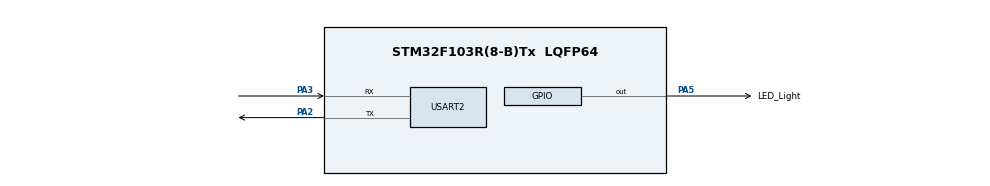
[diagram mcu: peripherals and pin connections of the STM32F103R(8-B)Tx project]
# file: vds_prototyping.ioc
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Dma.Request0=USART2_TX
Dma.USART2_TX.0.Direction=DMA_MEMORY_TO_PERIPH
Dma.USART2_TX.0.Instance=DMA1_Channel7
Dma.USART2_TX.0.MemDataAlignment=DMA_MDATAALIGN_BYTE
Dma.USART2_TX.0.MemInc=DMA_MINC_ENABLE
Dma.USART2_TX.0.Mode=DMA_NORMAL
Dma.USART2_TX.0.PeriphDataAlignment=DMA_PDATAALIGN_BYTE
Dma.USART2_TX.0.PeriphInc=DMA_PINC_DISABLE
Dma.USART2_TX.0.Priority=DMA_PRIORITY_LOW
FREERTOS.Tasks01=task1,24,128,startTask1,Default,NULL,Dynamic,NULL,NULL;myTask02,25,128,StartTask02,Default,NULL,Dynamic,NULL,NULL
Mcu.Family=STM32F1
Mcu.Name=STM32F103R(8-B)Tx
Mcu.Package=LQFP64
NVIC.DMA1_Channel7_IRQn=true\:5\:0\:false\:false\:true\:true\:false\:true\:true
NVIC.PriorityGroup=NVIC_PRIORITYGROUP_4
NVIC.TIM4_IRQn=true\:15\:0\:false\:false\:true\:false\:false\:true\:true
NVIC.TimeBase=TIM4_IRQn
NVIC.TimeBaseIP=TIM4
PA2.Mode=Asynchronous
PA2.Signal=USART2_TX
PA3.Mode=Asynchronous
PA3.Signal=USART2_RX
PA5.GPIO_Label=LED_Light
PA5.Signal=GPIO_Output
ProjectManager.HeapSize=0x200
ProjectManager.StackSize=0x400
ProjectManager.TargetToolchain=STM32CubeIDE
RCC.APB1Freq_Value=8000000
RCC.APB2Freq_Value=8000000
USART2.VirtualMode=VM_ASYNC
VP_FREERTOS_VS_CMSIS_V2.Mode=CMSIS_V2
VP_SYS_VS_tim4.Mode=TIM4
board=custom

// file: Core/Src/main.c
/* USER CODE BEGIN Header */
/**
  ******************************************************************************
  * @file           : main.c
  * @brief          : Main program body
  ******************************************************************************
  * @attention
  *
  * Copyright (c) 2024 STMicroelectronics.
  * All rights reserved.
  *
  * This software is licensed under terms that can be found in the LICENSE file
  * in the root directory of this software component.
  * If no LICENSE file comes with this software, it is provided AS-IS.
  *
  ******************************************************************************
  */
/* USER CODE END Header */
#include "main.h"
#include "cmsis_os.h"

/* USER CODE BEGIN Includes */
#include "stdio.h"
#include "string.h"

/* USER CODE END Includes */

UART_HandleTypeDef huart2;
DMA_HandleTypeDef hdma_usart2_tx;

/* Definitions for task1 */
osThreadId_t task1Handle;
const osThreadAttr_t task1_attributes = {
  .name = "task1",
  .stack_size = 128 * 4,
  .priority = (osPriority_t) osPriorityNormal,
};
/* Definitions for myTask02 */
osThreadId_t myTask02Handle;
const osThreadAttr_t myTask02_attributes = {
  .name = "myTask02",
  .stack_size = 128 * 4,
  .priority = (osPriority_t) osPriorityNormal1,
};
/* USER CODE BEGIN PV */
char msg[] =     "Lorem ipsum \r\n DMA Transfer Test \r\n" \
	             "Lorem ipsum \r\n DMA Transfer Test \r\n" \
	             "Lorem ipsum \r\n DMA Transfer Test \r\n" \
	             "Hello World \r\n";

int count=0;
/* USER CODE END PV */

void SystemClock_Config(void);
static void MX_GPIO_Init(void);
static void MX_DMA_Init(void);
static void MX_USART2_UART_Init(void);
void startTask1(void *argument);
void StartTask02(void *argument);

/* USER CODE BEGIN PFP */
#ifdef __GNUC__
#define PUTCHAR_PROTOTYPE int __io_putchar(int ch)
#else
#define PUTCHAR_PROTOTYPE int fputc(int ch, FILE *f)
#endif
PUTCHAR_PROTOTYPE
{
  HAL_UART_Transmit(&huart2, (uint8_t *)&ch, 1, HAL_MAX_DELAY);
  return ch;
}

//custom callback function
void DMATransferComplete(DMA_HandleTypeDef *hdma);

/* USER CODE END PFP */

int main(void)
{

  /* MCU Configuration--------------------------------------------------------*/

  /* Reset of all peripherals, Initializes the Flash interface and the Systick. */
  HAL_Init();

  /* Configure the system clock */
  SystemClock_Config();

  /* Initialize all configured peripherals */
  MX_GPIO_Init();
  MX_DMA_Init();
  MX_USART2_UART_Init();
  /* USER CODE BEGIN 2 */
  HAL_DMA_RegisterCallback(&hdma_usart2_tx, HAL_DMA_XFER_CPLT_CB_ID,
		  	  	  	  	  &DMATransferComplete); //Register our own callback

  /* USER CODE END 2 */

  /* Init scheduler */
  osKernelInitialize();

  /* Create the thread(s) */
  /* creation of task1 */
  task1Handle = osThreadNew(startTask1, NULL, &task1_attributes);

  /* creation of myTask02 */
  myTask02Handle = osThreadNew(StartTask02, NULL, &myTask02_attributes);

  /* Start scheduler */
  osKernelStart();

  /* We should never get here as control is now taken by the scheduler */
  /* Infinite loop */
  while (1)
  {

  }
}

void SystemClock_Config(void)
{
  RCC_OscInitTypeDef RCC_OscInitStruct = {0};
  RCC_ClkInitTypeDef RCC_ClkInitStruct = {0};

  /** Initializes the RCC Oscillators according to the specified parameters
  * in the RCC_OscInitTypeDef structure.
  */
  RCC_OscInitStruct.OscillatorType = RCC_OSCILLATORTYPE_HSI;
  RCC_OscInitStruct.HSIState = RCC_HSI_ON;
  RCC_OscInitStruct.HSICalibrationValue = RCC_HSICALIBRATION_DEFAULT;
  RCC_OscInitStruct.PLL.PLLState = RCC_PLL_NONE;
  if (HAL_RCC_OscConfig(&RCC_OscInitStruct) != HAL_OK)
  {
    Error_Handler();
  }

  /** Initializes the CPU, AHB and APB buses clocks
  */
  RCC_ClkInitStruct.ClockType = RCC_CLOCKTYPE_HCLK|RCC_CLOCKTYPE_SYSCLK
                              |RCC_CLOCKTYPE_PCLK1|RCC_CLOCKTYPE_PCLK2;
  RCC_ClkInitStruct.SYSCLKSource = RCC_SYSCLKSOURCE_HSI;
  RCC_ClkInitStruct.AHBCLKDivider = RCC_SYSCLK_DIV1;
  RCC_ClkInitStruct.APB1CLKDivider = RCC_HCLK_DIV1;
  RCC_ClkInitStruct.APB2CLKDivider = RCC_HCLK_DIV1;

  if (HAL_RCC_ClockConfig(&RCC_ClkInitStruct, FLASH_LATENCY_0) != HAL_OK)
  {
    Error_Handler();
  }
}

static void MX_USART2_UART_Init(void)
{

  huart2.Instance = USART2;
  huart2.Init.BaudRate = 115200;
  huart2.Init.WordLength = UART_WORDLENGTH_8B;
  huart2.Init.StopBits = UART_STOPBITS_1;
  huart2.Init.Parity = UART_PARITY_NONE;
  huart2.Init.Mode = UART_MODE_TX_RX;
  huart2.Init.HwFlowCtl = UART_HWCONTROL_NONE;
  huart2.Init.OverSampling = UART_OVERSAMPLING_16;
  if (HAL_UART_Init(&huart2) != HAL_OK)
  {
    Error_Handler();
  }

}

static void MX_DMA_Init(void)
{

  /* DMA controller clock enable */
  __HAL_RCC_DMA1_CLK_ENABLE();

  /* DMA interrupt init */
  /* DMA1_Channel7_IRQn interrupt configuration */
  HAL_NVIC_SetPriority(DMA1_Channel7_IRQn, 5, 0);
  HAL_NVIC_EnableIRQ(DMA1_Channel7_IRQn);

}

static void MX_GPIO_Init(void)
{
  GPIO_InitTypeDef GPIO_InitStruct = {0};

  /* GPIO Ports Clock Enable */
  __HAL_RCC_GPIOA_CLK_ENABLE();

  /*Configure GPIO pin Output Level */
  HAL_GPIO_WritePin(LED_Light_GPIO_Port, LED_Light_Pin, GPIO_PIN_RESET);

  /*Configure GPIO pin : LED_Light_Pin */
  GPIO_InitStruct.Pin = LED_Light_Pin;
  GPIO_InitStruct.Mode = GPIO_MODE_OUTPUT_PP;
  GPIO_InitStruct.Pull = GPIO_NOPULL;
  GPIO_InitStruct.Speed = GPIO_SPEED_FREQ_LOW;
  HAL_GPIO_Init(LED_Light_GPIO_Port, &GPIO_InitStruct);

}

/* USER CODE BEGIN 4 */
void DMATransferComplete(DMA_HandleTypeDef *hdma){
	//custom callback function
	huart2.Instance->CR3 &= ~USART_CR3_DMAT;

	printf("DMA Transfer Completed. %d \r\n", ++count);
	//Toggle LED to indicate finished
	HAL_GPIO_TogglePin(LED_Light_GPIO_Port, LED_Light_Pin);
}
/* USER CODE END 4 */

void startTask1(void *argument)
{
  /* USER CODE BEGIN 5 */
  /* Infinite loop */
  for(;;)
  {
	huart2.Instance->CR3 |= USART_CR3_DMAT;
	HAL_DMA_Start_IT(&hdma_usart2_tx, (uint32_t)msg, (uint32_t)&huart2.Instance->DR, strlen(msg));
//	printf("1: Hello world\r\n");
    osDelay(1000);
  }
  /* USER CODE END 5 */
}

void StartTask02(void *argument)
{
  /* USER CODE BEGIN StartTask02 */
  /* Infinite loop */
  for(;;)
  {
//	printf("1: Hello world\r\n");
    osDelay(1);
  }
  /* USER CODE END StartTask02 */
}

void HAL_TIM_PeriodElapsedCallback(TIM_HandleTypeDef *htim)
{
  if (htim->Instance == TIM4) {
    HAL_IncTick();
  }
}

void Error_Handler(void)
{
  __disable_irq();
  while (1)
  {
  }
}
